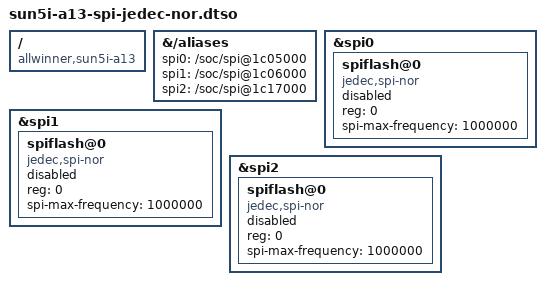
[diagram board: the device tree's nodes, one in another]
/dts-v1/;
/plugin/;

/ {
	compatible = "allwinner,sun5i-a13";

	fragment@0 {
		target-path = "/aliases";
		__overlay__ {
			spi0 = "/soc/spi@1c05000";
			spi1 = "/soc/spi@1c06000";
			spi2 = "/soc/spi@1c17000";
		};
	};

	fragment@1 {
		target = <&spi0>;
		__overlay__ {
			#address-cells = <1>;
			#size-cells = <0>;
			spiflash@0 {
				compatible = "jedec,spi-nor";
				status = "disabled";
				reg = <0>;
				spi-max-frequency = <1000000>;
			};
		};
	};

	fragment@2 {
		target = <&spi1>;
		__overlay__ {
			#address-cells = <1>;
			#size-cells = <0>;
			spiflash@0 {
				compatible = "jedec,spi-nor";
				status = "disabled";
				reg = <0>;
				spi-max-frequency = <1000000>;
			};
		};
	};

	fragment@3 {
		target = <&spi2>;
		__overlay__ {
			#address-cells = <1>;
			#size-cells = <0>;
			spiflash@0 {
				compatible = "jedec,spi-nor";
				status = "disabled";
				reg = <0>;
				spi-max-frequency = <1000000>;
			};
		};
	};
};
